# Z20K14xM register map
Vendor: Zhixin Semiconductor; Series: Z20K14xM; File version: 0.1.0
CPU: CM4 r0p1, little endian, no MPU, FPU, 4 interrupt priority bits
Registers are 32-bit, read-write, reset 0x0 unless marked. A register's access mark holds for its fields unless they carry their own. Offsets are from the block's base; [hi:lo] are bit positions; {n}, {i} and the like mark numbered series.

## REGFILE
Base 0x4007C000
{0x0+4i} REGFILE_REGn{i} (i=0..31) — register file register
  [31:0] DATA

## SERU
Base 0x4007F000
0x00 SERU_VERSION ro reset 0x10001 — Reserved
0x04 SERU_PARAM ro — Reserved
  [31:0] PARAM — parameter
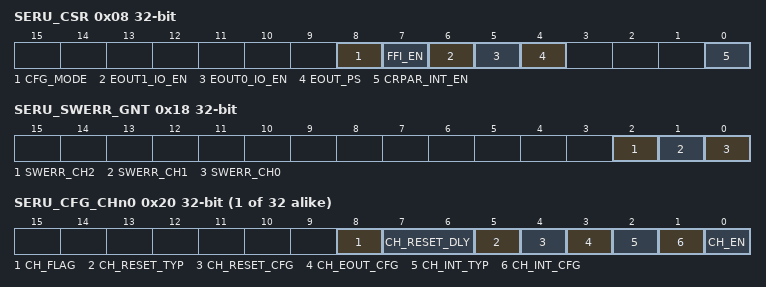
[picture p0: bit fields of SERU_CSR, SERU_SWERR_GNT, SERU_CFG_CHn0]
0x08 SERU_CSR — Reserved
  [8] CFG_MODE — configure mode
  [7] FFI_EN — fake fault injection enable
  [6] EOUT1_IO_EN — EOUT1 to external pin
  [5] EOUT0_IO_EN — EOUT0 to external pin
  [4] EOUT_PS — EOUT Polarity Selection
  [0] CRPAR_INT_EN — register parity error int enable
0x0C SERU_INTF — Reserved
  [0] S_CRPAR_ERR — register parity error flag
0x10 SERU_CFG_KEY — Reserved
  [31:0] KEY — configure mode key
0x14 SERU_CH_FFI — Reserved
  [31:0] CH_FFI — Fake fault injection
0x18 SERU_SWERR_GNT — Reserved
  [2] SWERR_CH2 — software error generate
  [1] SWERR_CH1 — software error generate
  [0] SWERR_CH0 — software error generate
0x1C SERU_CH_FLAG — Reserved
  [31:0] CH_FLAG — channel error flag
{0x20+4i} SERU_CFG_CHn{i} (i=0..31) — Reserved
  [8] CH_FLAG — channel error flag
  [7:6] CH_RESET_DLY — reset generation delay
  [5] CH_RESET_TYP — select RESET type
  [4] CH_RESET_CFG — enable RESET generation
  [3] CH_EOUT_CFG — enable EOUT report
  [2] CH_INT_TYP — enable INT type
  [1] CH_INT_CFG — enable INT generation
  [0] CH_EN — enable channel

## GPIO
Base 0x400FF000
0x00 GPIOA_PDOR — Port Data Output Register(GPIOA_PDOR)
  [31:0] PDO — Port Data Output
0x04 GPIOA_PSOR wo — Port Set Output Register(GPIOA_PSOR)
  [31:0] PSO — Port Set Output
0x08 GPIOA_PCOR wo — Port Clear Output Register(GPIOA_PCOR)
  [31:0] PCO — Port Clear Output
0x0C GPIOA_PTOR wo — Port Toggle Output Register(GPIOA_PTOR)
  [31:0] PTO — Port Toggle Output
0x10 GPIOA_PDIR ro — Port Data Input Register(GPIOA_PDIR)
  [31:0] PDI — Port Data Input
0x14 GPIOA_PDDR — Port Data Direction Register(GPIOA_PDDR)
  [31:0] PDD — Port Data Direction
0x18 GPIOA_PIDR ro — Port Input Disable Register(GPIOA_PIDR)
0x40 GPIOB_PDOR — Port Data Output Register(GPIOB_PDOR)
  [31:0] PDO — Port Data Output
0x44 GPIOB_PSOR wo — Port Set Output Register(GPIOB_PSOR)
  [31:0] PSO — Port Set Output
0x48 GPIOB_PCOR wo — Port Clear Output Register(GPIOB_PCOR)
  [31:0] PCO — Port Clear Output
0x4C GPIOB_PTOR wo — Port Toggle Output Register(GPIOB_PTOR)
  [31:0] PTO — Port Toggle Output
0x50 GPIOB_PDIR ro — Port Data Input Register(GPIOB_PDIR)
  [31:0] PDI — Port Data Input
0x54 GPIOB_PDDR — Port Data Direction Register(GPIOB_PDDR)
  [31:0] PDD — Port Data Direction
0x58 GPIOB_PIDR ro — Port Input Disable Register(GPIOB_PIDR)
0x80 GPIOC_PDOR — Port Data Output Register(GPIOC_PDOR)
  [31:0] PDO — Port Data Output
0x84 GPIOC_PSOR wo — Port Set Output Register(GPIOC_PSOR)
  [31:0] PSO — Port Set Output
0x88 GPIOC_PCOR wo — Port Clear Output Register(GPIOC_PCOR)
  [31:0] PCO — Port Clear Output
0x8C GPIOC_PTOR wo — Port Toggle Output Register(GPIOC_PTOR)
  [31:0] PTO — Port Toggle Output
0x90 GPIOC_PDIR ro — Port Data Input Register(GPIOC_PDIR)
  [31:0] PDI — Port Data Input
0x94 GPIOC_PDDR — Port Data Direction Register(GPIOC_PDDR)
  [31:0] PDD — Port Data Direction
0x98 GPIOC_PIDR ro — Port Input Disable Register(GPIOC_PIDR)
0xC0 GPIOD_PDOR — Port Data Output Register(GPIOD_PDOR)
  [31:0] PDO — Port Data Output
0xC4 GPIOD_PSOR wo — Port Set Output Register(GPIOD_PSOR)
  [31:0] PSO — Port Set Output
0xC8 GPIOD_PCOR wo — Port Clear Output Register(GPIOD_PCOR)
  [31:0] PCO — Port Clear Output
0xCC GPIOD_PTOR wo — Port Toggle Output Register(GPIOD_PTOR)
  [31:0] PTO — Port Toggle Output
0xD0 GPIOD_PDIR ro — Port Data Input Register(GPIOD_PDIR)
  [31:0] PDI — Port Data Input
0xD4 GPIOD_PDDR — Port Data Direction Register(GPIOD_PDDR)
  [31:0] PDD — Port Data Direction
0xD8 GPIOD_PIDR ro — Port Input Disable Register(GPIOD_PIDR)
0x100 GPIOE_PDOR — Port Data Output Register(GPIOE_PDOR)
  [31:0] PDO — Port Data Output
0x104 GPIOE_PSOR wo — Port Set Output Register(GPIOE_PSOR)
  [31:0] PSO — Port Set Output
0x108 GPIOE_PCOR wo — Port Clear Output Register(GPIOE_PCOR)
  [31:0] PCO — Port Clear Output
0x10C GPIOE_PTOR wo — Port Toggle Output Register(GPIOE_PTOR)
  [31:0] PTO — Port Toggle Output
0x110 GPIOE_PDIR ro — Port Data Input Register(GPIOE_PDIR)
  [31:0] PDI — Port Data Input
0x114 GPIOE_PDDR — Port Data Direction Register(GPIOE_PDDR)
  [31:0] PDD — Port Data Direction
0x118 GPIOE_PIDR ro — Port Input Disable Register(GPIOE_PIDR)
